VERSION ""

NS_ :

BS_:

BU_: XXX

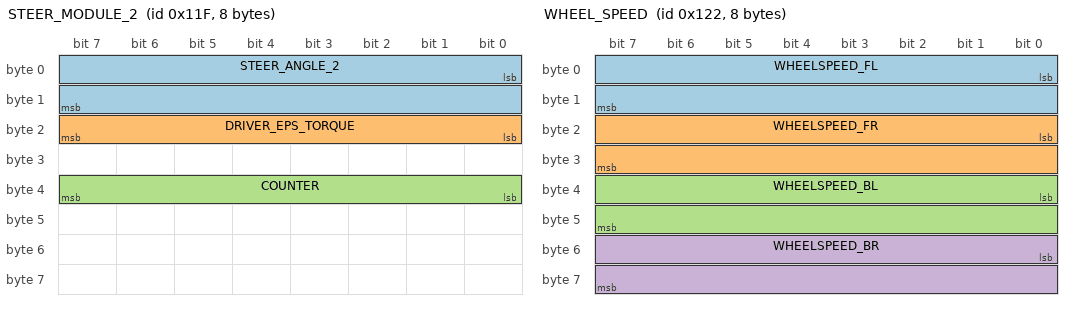
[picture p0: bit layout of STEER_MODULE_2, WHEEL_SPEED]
BO_ 287 STEER_MODULE_2: 8 XXX
 SG_ STEER_ANGLE_2 : 0|16@1- (0.1,0) [0|65535] "" XXX
 SG_ DRIVER_EPS_TORQUE : 16|8@1+ (1,0) [0|255] "" XXX
 SG_ COUNTER : 39|8@0+ (1,0) [0|255] "" XXX

BO_ 290 WHEEL_SPEED: 8 XXX
 SG_ WHEELSPEED_FL : 0|16@1+ (0.1,0) [0|65535] "" XXX
 SG_ WHEELSPEED_FR : 16|16@1+ (0.1,0) [0|65535] "" XXX
 SG_ WHEELSPEED_BL : 32|16@1+ (0.1,0) [0|65535] "" XXX
 SG_ WHEELSPEED_BR : 48|16@1+ (0.1,0) [0|65535] "" XXX

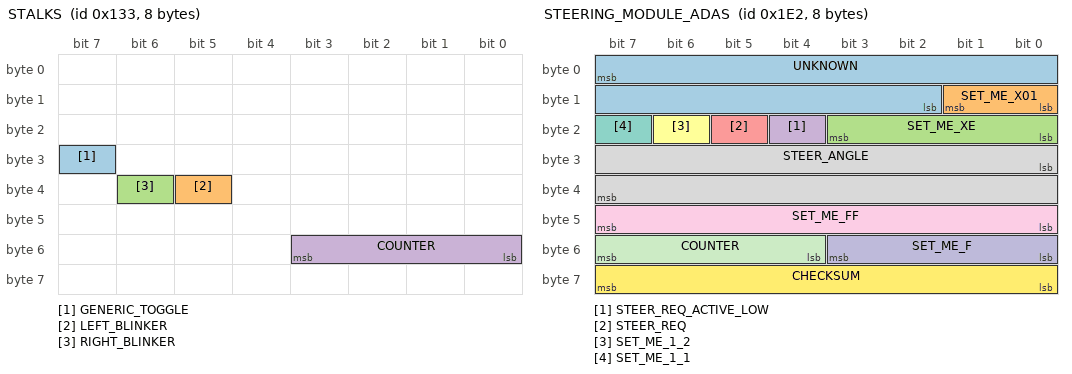
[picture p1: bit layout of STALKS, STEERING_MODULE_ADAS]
BO_ 307 STALKS: 8 XXX
 SG_ GENERIC_TOGGLE : 31|1@0+ (1,0) [0|1] "" XXX
 SG_ LEFT_BLINKER : 37|1@0+ (1,0) [0|1] "" XXX
 SG_ RIGHT_BLINKER : 38|1@0+ (1,0) [0|1] "" XXX
 SG_ COUNTER : 48|4@1+ (1,0) [0|15] "" XXX

BO_ 482 STEERING_MODULE_ADAS: 8 XXX
 SG_ UNKNOWN : 7|14@0- (1,0) [0|65535] "" XXX
 SG_ SET_ME_X01 : 8|2@1+ (1,0) [0|3] "" XXX
 SG_ SET_ME_XE : 16|4@1+ (1,0) [0|15] "" XXX
 SG_ STEER_REQ_ACTIVE_LOW : 20|1@0+ (1,0) [0|1] "" XXX
 SG_ STEER_REQ : 21|1@0+ (1,0) [0|1] "" XXX
 SG_ SET_ME_1_2 : 22|1@0+ (1,0) [0|3] "" XXX
 SG_ SET_ME_1_1 : 23|1@0+ (1,0) [0|1] "" XXX
 SG_ STEER_ANGLE : 24|16@1- (0.1,0) [0|255] "" XXX
 SG_ SET_ME_FF : 47|8@0+ (1,0) [0|255] "" XXX
 SG_ SET_ME_F : 48|4@1+ (1,0) [0|15] "" XXX
 SG_ COUNTER : 55|4@0+ (1,0) [0|15] "" XXX
 SG_ CHECKSUM : 56|8@1+ (1,0) [0|255] "" XXX

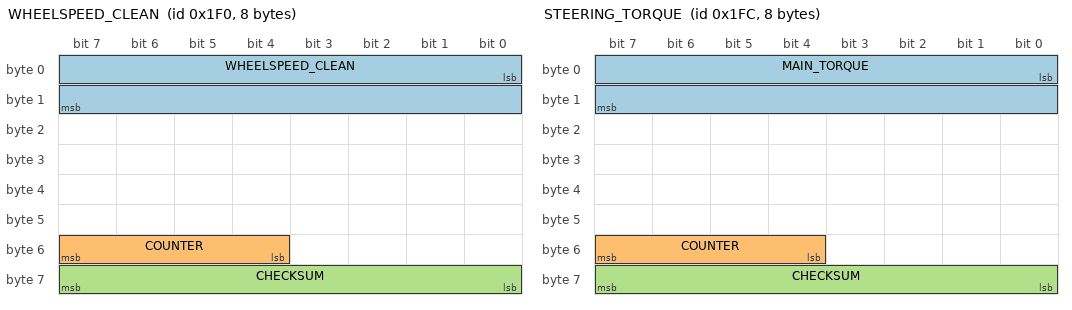
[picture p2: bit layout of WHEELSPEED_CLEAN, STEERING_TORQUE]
BO_ 496 WHEELSPEED_CLEAN: 8 XXX
 SG_ WHEELSPEED_CLEAN : 0|16@1+ (0.1,0) [0|65535] "" XXX
 SG_ COUNTER : 55|4@0+ (1,0) [0|15] "" XXX
 SG_ CHECKSUM : 56|8@1+ (1,0) [0|255] "" XXX

BO_ 508 STEERING_TORQUE: 8 XXX
 SG_ MAIN_TORQUE : 0|16@1- (0.1,0) [0|65535] "" XXX
 SG_ COUNTER : 55|4@0+ (1,0) [0|15] "" XXX
 SG_ CHECKSUM : 56|8@1+ (1,0) [0|255] "" XXX

BO_ 544 PEDAL_PRESSED: 8 XXX
 SG_ PEDAL_PRESSED_ACTIVE_LOW : 12|1@0+ (1,0) [0|1] "" XXX

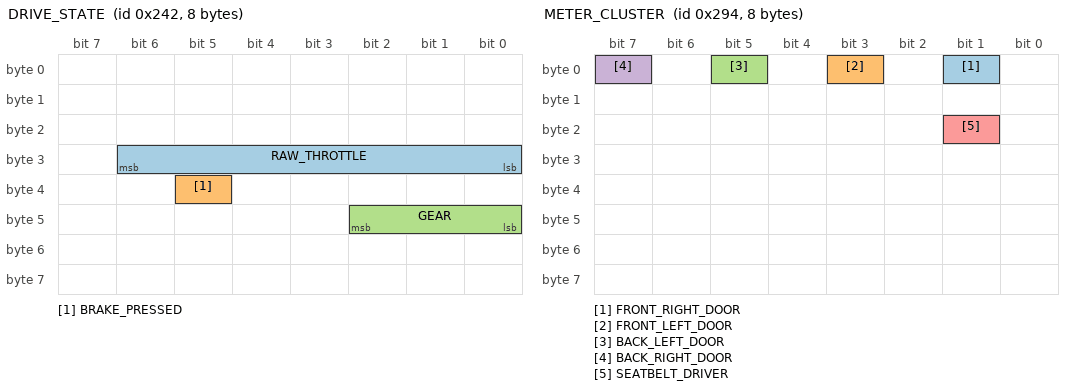
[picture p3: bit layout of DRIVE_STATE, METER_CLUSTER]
BO_ 578 DRIVE_STATE: 8 XXX
 SG_ RAW_THROTTLE : 30|7@0+ (1,0) [0|127] "" XXX
 SG_ BRAKE_PRESSED : 37|1@0+ (1,0) [0|1] "" XXX
 SG_ GEAR : 40|3@1+ (1,0) [0|7] "" XXX

BO_ 660 METER_CLUSTER: 8 XXX
 SG_ FRONT_RIGHT_DOOR : 1|1@1+ (1,0) [0|511] "" XXX
 SG_ FRONT_LEFT_DOOR : 3|1@0+ (1,0) [0|1] "" XXX
 SG_ BACK_LEFT_DOOR : 5|1@1+ (1,0) [0|511] "" XXX
 SG_ BACK_RIGHT_DOOR : 7|1@0+ (1,0) [0|1] "" XXX
 SG_ SEATBELT_DRIVER : 17|1@0+ (1,0) [0|1] "" XXX

BO_ 692 ADAS2: 8 XXX

BO_ 790 LKAS_HUD_ADAS: 8 XXX
 SG_ HMA : 4|5@0+ (1,0) [0|7] "" XXX
 SG_ STEER_ACTIVE_1_1 : 5|1@0+ (1,0) [0|1] "" XXX
 SG_ LSS_STATE : 7|2@0+ (1,0) [0|1] "" XXX
 SG_ PT3 : 8|2@1+ (1,0) [0|3] "" XXX
 SG_ HAND_ON_WHEEL_WARNING : 10|1@0+ (1,0) [0|1] "" XXX
 SG_ PT2 : 11|5@1+ (1,0) [0|31] "" XXX
 SG_ SET_ME_XFF : 23|8@0+ (1,0) [0|255] "" XXX
 SG_ SET_ME_X5F : 31|8@0+ (1,0) [0|255] "" XXX
 SG_ SET_ME_1_2 : 32|1@0+ (1,0) [0|1] "" XXX
 SG_ PT5 : 33|2@1+ (1,0) [0|3] "" XXX
 SG_ STEER_ACTIVE_1_3 : 35|1@0+ (1,0) [0|1] "" XXX
 SG_ STEER_ACTIVE_ACTIVE_LOW : 36|1@0+ (1,0) [0|1] "" XXX
 SG_ STEER_ACTIVE_1_2 : 37|1@0+ (1,0) [0|1] "" XXX
 SG_ PT4 : 39|2@0+ (1,0) [0|3] "" XXX
 SG_ TSR : 47|8@0+ (1,0) [0|255] "" XXX
 SG_ SETTINGS : 48|4@1+ (1,0) [0|15] "" XXX
 SG_ COUNTER : 55|4@0+ (1,0) [0|15] "" XXX
 SG_ CHECKSUM : 63|8@0+ (1,0) [0|255] "" XXX

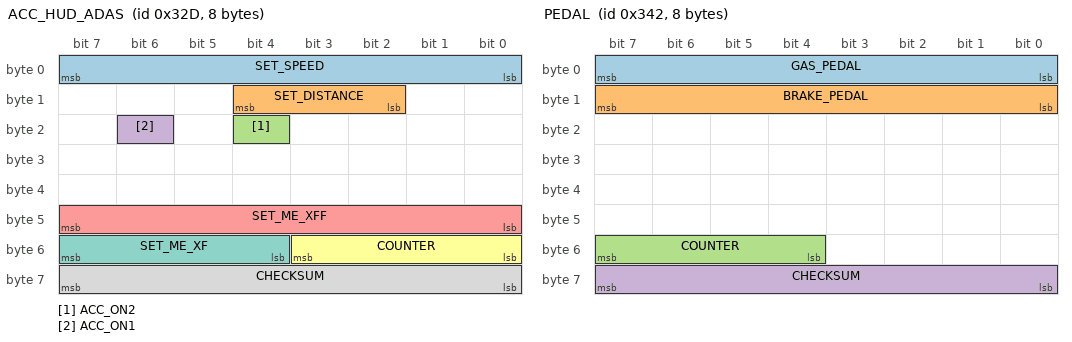
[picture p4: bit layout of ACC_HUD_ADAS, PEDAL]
BO_ 813 ACC_HUD_ADAS: 8 XXX
 SG_ SET_SPEED : 0|8@1+ (0.5,0) [0|255] "" XXX
 SG_ SET_DISTANCE : 12|3@0+ (1,0) [0|7] "" XXX
 SG_ ACC_ON2 : 20|1@0+ (1,0) [0|1] "" XXX
 SG_ ACC_ON1 : 22|1@0+ (1,0) [0|1] "" XXX
 SG_ SET_ME_XFF : 47|8@0+ (1,0) [0|255] "" XXX
 SG_ COUNTER : 48|4@1+ (1,0) [0|15] "" XXX
 SG_ SET_ME_XF : 55|4@0+ (1,0) [0|15] "" XXX
 SG_ CHECKSUM : 56|8@1+ (1,0) [0|255] "" XXX

BO_ 814 ACC_CMD: 8 XXX
 SG_ ACCEL_CMD : 0|8@1+ (1,-100) [0|255] "" XXX
 SG_ ACC_ON_1 : 9|1@0+ (1,0) [0|1] "" XXX
 SG_ SET_ME_25_1 : 10|6@1+ (1,0) [0|255] "" XXX
 SG_ ACC_ON_2 : 17|1@0+ (1,0) [0|1] "" XXX
 SG_ SET_ME_25_2 : 18|6@1+ (1,0) [0|255] "" XXX
 SG_ DECEL_FACTOR : 24|4@1+ (1,0) [0|15] "" XXX
 SG_ SET_ME_X8 : 31|4@0+ (1,0) [0|255] "" XXX
 SG_ ACCEL_FACTOR : 32|4@1+ (1,0) [0|15] "" XXX
 SG_ CMD_REQ_ACTIVE_LOW : 36|1@0+ (1,0) [0|255] "" XXX
 SG_ SET_ME_1 : 38|1@0+ (1,0) [0|1] "" XXX
 SG_ STANDSTILL_RESUME : 39|1@0+ (1,0) [0|1] "" XXX
 SG_ STANDSTILL_STATE : 40|1@0+ (1,0) [0|1] "" XXX
 SG_ ACC_REQ_NOT_STANDSTILL : 43|1@0+ (1,0) [0|1] "" XXX
 SG_ ACC_CONTROLLABLE_AND_ON : 44|1@0+ (1,0) [0|1] "" XXX
 SG_ ACC_OVERRIDE_OR_STANDSTILL : 45|1@0+ (1,0) [0|1] "" XXX
 SG_ COUNTER : 48|4@1+ (1,0) [0|15] "" XXX
 SG_ SET_ME_XF : 55|4@0+ (1,0) [0|15] "" XXX
 SG_ CHECKSUM : 56|8@1+ (1,0) [0|255] "" XXX

BO_ 815 ADAS3: 8 XXX

BO_ 834 PEDAL: 8 XXX
 SG_ GAS_PEDAL : 0|8@1+ (0.01,0) [0|255] "" XXX
 SG_ BRAKE_PEDAL : 8|8@1+ (0.01,0) [0|255] "" XXX
 SG_ COUNTER : 55|4@0+ (1,0) [0|15] "" XXX
 SG_ CHECKSUM : 56|8@1+ (1,0) [0|255] "" XXX

BO_ 843 ADAS4: 8 XXX

BO_ 884 ADAS5: 8 XXX

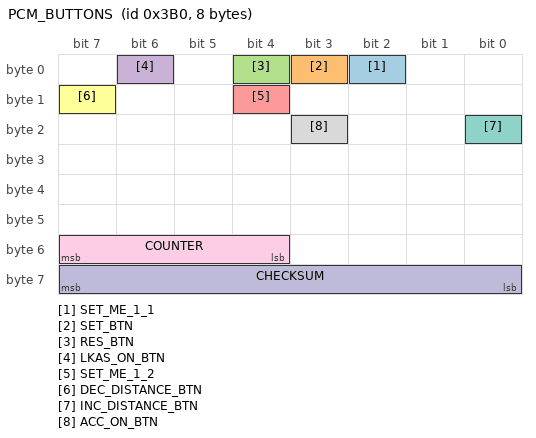
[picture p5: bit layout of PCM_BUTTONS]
BO_ 944 PCM_BUTTONS: 8 XXX
 SG_ SET_ME_1_1 : 2|1@0+ (1,0) [0|1] "" XXX
 SG_ SET_BTN : 3|1@0+ (1,0) [0|1] "" XXX
 SG_ RES_BTN : 4|1@0+ (1,0) [0|1] "" XXX
 SG_ LKAS_ON_BTN : 6|1@0+ (1,0) [0|1] "" XXX
 SG_ SET_ME_1_2 : 12|1@0+ (1,0) [0|1] "" XXX
 SG_ DEC_DISTANCE_BTN : 15|1@0+ (1,0) [0|1] "" XXX
 SG_ INC_DISTANCE_BTN : 16|1@0+ (1,0) [0|1] "" XXX
 SG_ ACC_ON_BTN : 19|1@0+ (1,0) [0|1] "" XXX
 SG_ COUNTER : 55|4@0+ (1,0) [0|15] "" XXX
 SG_ CHECKSUM : 63|8@0+ (1,0) [0|255] "" XXX

BO_ 1028 HVAC: 8 XXX

BO_ 1048 BSM: 8 XXX
 SG_ RIGHT_APPROACH : 17|1@0+ (1,0) [0|1] "" XXX
 SG_ LEFT_APPROACH : 23|1@0+ (1,0) [0|1] "" XXX

BO_ 1074 ADAS6: 8 XXX

CM_ BO_ 1028 "This is the HVAC control of the Car. 
The first line or 0 Byte. Corresponds to Auto On/Off. 
the second byte is the fan power.
Fourth and fifth byte are for hvac control";
VAL_ 578 GEAR 4 "D" 2 "R" 1 "P";
VAL_ 813 SET_DISTANCE 8 "4bar" 4 "3bar" 2 "2bar" 1 "1bar";
